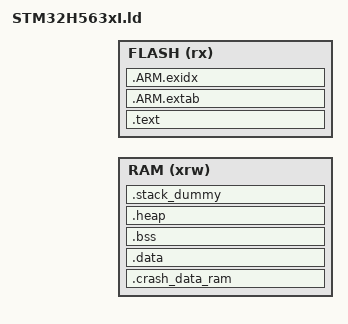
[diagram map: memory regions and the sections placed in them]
/*
******************************************************************************
**
** @file        : LinkerScript.ld
**
** @author      : Auto-generated by STM32CubeIDE
**
** @brief       : Linker script for STM32H563ZITx Device from STM32H5 series
**                      2Mbytes FLASH
**                      640Kbytes RAM
**
**                Set heap size, stack size and stack location according
**                to application requirements.
**
**                Set memory bank area and size if external memory is used
**
**  Target      : STMicroelectronics STM32
**
**  Distribution: The file is distributed as is, without any warranty
**                of any kind.
**
******************************************************************************
** @attention
**
** Copyright (c) 2023 STMicroelectronics.
** All rights reserved.
**
** This software is licensed under terms that can be found in the LICENSE file
** in the root directory of this software component.
** If no LICENSE file comes with this software, it is provided AS-IS.
**
******************************************************************************
*/

#include "../cmsis_nvic.h"


#if !defined(MBED_APP_START)
  #define MBED_APP_START  MBED_ROM_START
#endif

#if !defined(MBED_APP_SIZE)
  #define MBED_APP_SIZE  MBED_ROM_SIZE
#endif

M_CRASH_DATA_RAM_SIZE = 0x100;

#if !defined(MBED_CONF_TARGET_BOOT_STACK_SIZE)
    /* This value is normally defined by the tools
       to 0x1000 for bare metal and 0x400 for RTOS */
    #define MBED_CONF_TARGET_BOOT_STACK_SIZE  0x400
#endif

/* Round up VECTORS_SIZE to 8 bytes */
#define VECTORS_SIZE  (((NVIC_NUM_VECTORS * 4) + 7) & 0xFFFFFFF8)

/* Memories definition */
MEMORY
{
    RAM     (xrw)    : ORIGIN = (MBED_RAM_START + VECTORS_SIZE),  LENGTH = (MBED_RAM_SIZE - VECTORS_SIZE)
    FLASH    (rx)    : ORIGIN = MBED_APP_START,   LENGTH = MBED_APP_SIZE
}

/* Entry Point */
ENTRY(Reset_Handler)

/* Sections */
SECTIONS
{
    .text :
    {
        KEEP(*(.isr_vector))
        *(.text*)

        KEEP(*(.init))
        KEEP(*(.fini))

        /* .ctors */
        *crtbegin.o(.ctors)
        *crtbegin?.o(.ctors)
        *(EXCLUDE_FILE(*crtend?.o *crtend.o) .ctors)
        *(SORT(.ctors.*))
        *(.ctors)

        /* .dtors */
        *crtbegin.o(.dtors)
        *crtbegin?.o(.dtors)
        *(EXCLUDE_FILE(*crtend?.o *crtend.o) .dtors)
        *(SORT(.dtors.*))
        *(.dtors)

        *(.rodata*)

        KEEP(*(.eh_frame*))
    } > FLASH

    .ARM.extab :
    {
        *(.ARM.extab* .gnu.linkonce.armextab.*)
    } > FLASH

    __exidx_start = .;
    .ARM.exidx :
    {
        *(.ARM.exidx* .gnu.linkonce.armexidx.*)
    } > FLASH
    __exidx_end = .;

    __etext = .;
    _sidata = .;

    .crash_data_ram :
    {
        . = ALIGN(8);
        __CRASH_DATA_RAM__ = .;
        __CRASH_DATA_RAM_START__ = .; /* Create a global symbol at data start */
        KEEP(*(.keep.crash_data_ram))
        *(.m_crash_data_ram)     /* This is a user defined section */
        . += M_CRASH_DATA_RAM_SIZE;
        . = ALIGN(8);
        __CRASH_DATA_RAM_END__ = .; /* Define a global symbol at data end */
    } > RAM
    
    .data : AT (__etext)
    {
        __data_start__ = .;
        _sdata = .;
        *(vtable)
        *(.data*)

        . = ALIGN(8);
        /* preinit data */
        PROVIDE_HIDDEN (__preinit_array_start = .);
        KEEP(*(.preinit_array))
        PROVIDE_HIDDEN (__preinit_array_end = .);

        . = ALIGN(8);
        /* init data */
        PROVIDE_HIDDEN (__init_array_start = .);
        KEEP(*(SORT(.init_array.*)))
        KEEP(*(.init_array))
        PROVIDE_HIDDEN (__init_array_end = .);

        . = ALIGN(8);
        /* finit data */
        PROVIDE_HIDDEN (__fini_array_start = .);
        KEEP(*(SORT(.fini_array.*)))
        KEEP(*(.fini_array))
        PROVIDE_HIDDEN (__fini_array_end = .);

        KEEP(*(.jcr*))
        . = ALIGN(8);
        /* All data end */
        __data_end__ = .;
        _edata = .;

    } > RAM
    
    .bss :
    {
        . = ALIGN(8);
        __bss_start__ = .;
        _sbss = .;
        *(.bss*)
        *(COMMON)
        . = ALIGN(8);
        __bss_end__ = .;
        _ebss = .;
    } > RAM

    .heap (COPY):
    {
        __end__ = .;
        PROVIDE(end = .);
        *(.heap*)
        . = ORIGIN(RAM) + LENGTH(RAM) - MBED_CONF_TARGET_BOOT_STACK_SIZE;
        __HeapLimit = .;
    } > RAM

    /* .stack_dummy section doesn't contains any symbols. It is only
     * used for linker to calculate size of stack sections, and assign
     * values to stack symbols later */
    .stack_dummy (COPY):
    {
        *(.stack*)
    } > RAM

    /* Set stack top to end of RAM, and stack limit move down by
     * size of stack_dummy section */
    __StackTop = ORIGIN(RAM) + LENGTH(RAM);
    _estack = __StackTop;
    __StackLimit = __StackTop - MBED_CONF_TARGET_BOOT_STACK_SIZE;
    PROVIDE(__stack = __StackTop);

    /* Check if data + heap + stack exceeds RAM limit */
    ASSERT(__StackLimit >= __HeapLimit, "region RAM overflowed with stack")
}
